# GD32H71x_72x register map
File version: 1.0
CPU: CM7 r1p2, little endian, MPU, FPU, 4 interrupt priority bits
Registers are 32-bit, read-write, reset 0x0 unless marked. A register's access mark holds for its fields unless they carry their own. Offsets are from the block's base; [hi:lo] are bit positions; {n}, {i} and the like mark numbered series.

## ENDAT0 — EnDat 2.2 encoder interface module
Base 0x4000CC00
Same registers: ENDAT1 0x40002000
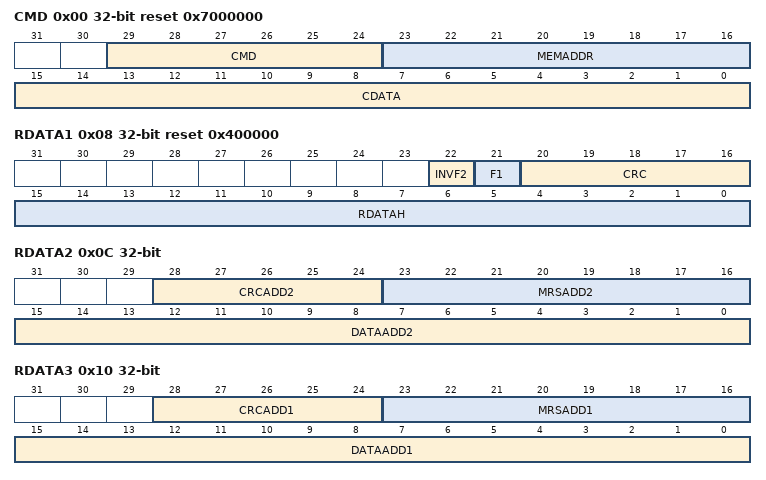
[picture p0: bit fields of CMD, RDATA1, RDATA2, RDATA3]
0x00 CMD reset 0x7000000 — ENDAT command register
  [29:24] CMD — EnDat communication mode code
  [23:16] MEMADDR — Memory range selection, address and port address of encoder
  [15:0] CDATA — Encoder receive communication data of instruction or parameters
0x04 RDATA0 ro — ENDAT received data register 0
  [31:0] RDATAL — Received data from encoder
0x08 RDATA1 ro reset 0x400000 — ENDAT received data register 1
  [22] INVF2 — The inverse of the safety-relevant error bit (F2) in the received data
  [21] F1 — The safety-relevant error bit (F1) in the received data
  [20:16] CRC — CRC in received data from encoder
  [15:0] RDATAH — Received data from encoder
0x0C RDATA2 ro — ENDAT received data register 2
  [28:24] CRCADD2 — CRC in additional information 2
  [23:16] MRSADD2 — MRS in additional information 2
  [15:0] DATAADD2 — Data in additional information 2
0x10 RDATA3 ro — ENDAT received data register 3
  [28:24] CRCADD1 — CRC in additional information 1
  [23:16] MRSADD1 — MRS in additional information 1
  [15:0] DATAADD1 — Data in additional information 1
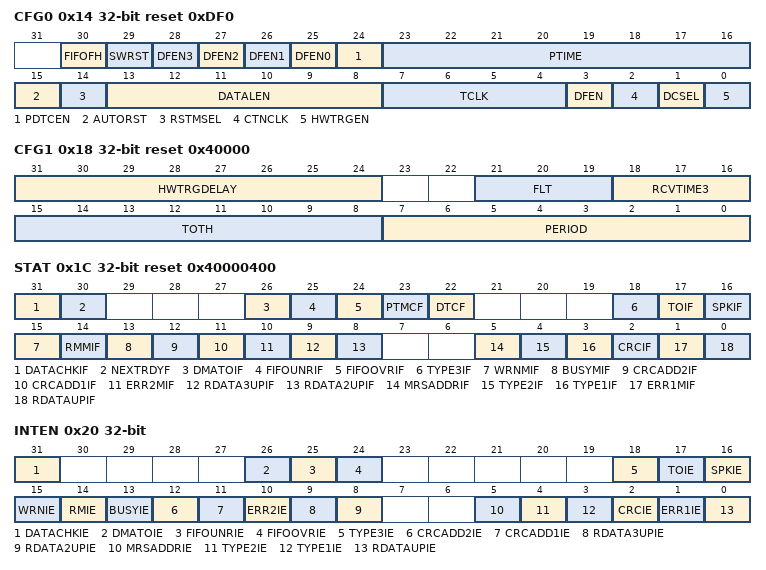
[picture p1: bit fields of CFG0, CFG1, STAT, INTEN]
0x14 CFG0 access per field reset 0xDF0 — ENDAT configuration register 0
  [30] FIFOFH wo — FIFO flush
  [29] SWRST wo — Software reset all registers of ENDAT module
  [n+25] DFEN{n} rw (n=0..3) — DMA request and FIFO enable for EDIM_ENDAT_RDATA{n} register
  [24] PDTCEN rw — Propagation delay time compensation enable
  [23:16] PTIME rw — Cable propagation time
  [15] AUTORST rw — Automatic reset of the status and error registers
  [14] RSTMSEL rw — Reset moment selection
  [13:8] DATALEN rw — EnDat data length
  [7:4] TCLK rw — Transmission clock for EnDat
  [3] DFEN rw — DMA request and FIFO enable
  [2] CTNCLK rw — Continuous clock mode
  [1] DCSEL rw — Data condition selection
  [0] HWTRGEN rw — Hardware trigger enable
0x18 CFG1 reset 0x40000 — ENDAT configuration register 1
  [31:24] HWTRGDELAY — Hardware trigger delay
  [21:19] FLT — Digital filter for data inputinterface from encoder
  [18:16] RCVTIME3 — Recovery time
  [15:8] TOTH — Frame transmission timeout threshold
  [7:0] PERIOD — Internal timer trigger period
0x1C STAT access per field reset 0x40000400 — ENDAT status register
  [31] DATACHKIF rw — Received data check interrupt flag
  [30] NEXTRDYF ro — Next transmisson ready flag
  [26] DMATOIF rw — DMA request timeout interrupt flag
  [25] FIFOUNRIF rw — FIFO underrun error interrupt flag
  [24] FIFOOVRIF rw — FIFO overrun error interrupt flag
  [23] PTMCF rw — Propagation time measurement completion flag
  [22] DTCF rw — Delay time compensation flag
  [18] TYPE3IF rw — Type error interrupt flag
  [17] TOIF rw — Frame transmission timeout interrupt flag
  [16] SPKIF rw — Spike detection interrupt flag
  [15] WRNMIF rw — Mirror interrupt flag for WRN bit transmitted in the EnDat protocol.
  [14] RMMIF rw — Mirror interrupt flag for RM bit transmitted in the EnDat protocol.
  [13] BUSYMIF rw — Mirror interrupt flag for BUSY bit transmitted in the EnDat protocol.
  [12] CRCADD2IF rw — CRC result interrupt flag of additional information 2
  [11] CRCADD1IF rw — CRC result interrupt flag of additional information 1
  [10] ERR2MIF rw — Mirror interrupt flag for Error message2 bit transmitted in the EnDat protocol (only with EnDat2.2 commands).
  [9] RDATA3UPIF rw — EDIM_ENDAT_RDATA3 register update interrupt flag
  [8] RDATA2UPIF rw — EDIM_ENDAT_RDATA2 register update interrupt flag
  [5] MRSADDRIF rw — MRS or address error interrupt flag
  [4] TYPE2IF rw — Type error interrupt flag
  [3] TYPE1IF rw — Type error interrupt flag
  [2] CRCIF rw — CRC error interrupt flag of the received data (position value, parameter or test value).
  [1] ERR1MIF rw — Mirror interrupt flag for Error message1 bit transmitted in the EnDat protocol
  [0] RDATAUPIF rw — EDIM_ENDAT_RDATA0 and EDIM_ENDAT_RADTA1 registers update interrupt flag
0x20 INTEN — ENDAT interrupt enable register
  [31] DATACHKIE — Interrupt enable for DATACHKIF
  [26] DMATOIE — Interrupt enable of DMATOIF
  [25] FIFOUNRIE — Interrupt enable of FIFOUNRIF
  [24] FIFOOVRIE — Interrupt enable of FIFOOVRIF
  [18] TYPE3IE — Interrupt enable of TYPE3IF
  [17] TOIE — Interrupt enable of TOIF
  [16] SPKIE — Interrupt enable of SPKIF
  [15] WRNIE — Interrupt enable of WRNMIF
  [14] RMIE — Interrupt enable of RMMIF
  [13] BUSYIE — Interrupt enable of BUSYMIF
  [12] CRCADD2IE — Interrupt enable of CRCADD2IF
  [11] CRCADD1IE — Interrupt enable of CRCADD1IF
  [10] ERR2IE — Interrupt enable of ERR2MIF
  [9] RDATA3UPIE — Interrupt enable of RDATA3UPIF
  [8] RDATA2UPIE — Interrupt enable of RDATA2UPIF
  [5] MRSADDRIE — Interrupt enable of MRSADDRIF
  [4] TYPE2IE — Interrupt enable of TYPE2IF
  [3] TYPE1IE — Interrupt enable of TYPE1IF
  [2] CRCIE — Interrupt enable of CRCIF
  [1] ERR1IE — Interrupt enable of ERR1MIF
  [0] RDATAUPIE — Interrupt enable of RDATAUPIF
0x24 SWT wo — ENDAT software trigger register
  [0] SWTR — Data transmission software trigger, cleared by hardware
0x128 FIFODATA ro — ENDAT FIFO data register
  [31:0] FIFODATA — FIFO data from EDIM_ENDAT_RDATAx registers
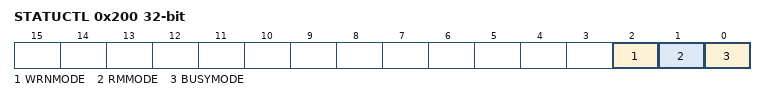
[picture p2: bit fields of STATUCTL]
0x200 STATUCTL — ENDAT status update control register
  [2] WRNMODE — WRNMIF status update mode
  [1] RMMODE — RMMIF status update mode
  [0] BUSYMODE — BUSYMIF status update mode
